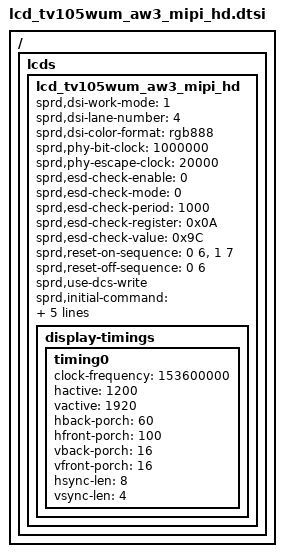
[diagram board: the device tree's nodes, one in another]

/*
 * tv105wum LCD config dtsi file for spreadtrum
 *
 * Copyright (C) 2018, Spreadtrum Communications Inc.
 * Copyright (C) 2023 Anhui Yunshu Zhihui Technology Co., Ltd.
 *
 * SPDX-License-Identifier: (GPL-2.0+ OR MIT)
 */

/ { lcds {
	lcd_tv105wum_aw3_mipi_hd: lcd_tv105wum_aw3_mipi_hd {

		sprd,dsi-work-mode = <1>; /* video burst mode*/
		sprd,dsi-lane-number = <4>;
		sprd,dsi-color-format = "rgb888";

		sprd,phy-bit-clock = <1000000>;	/* kbps */
		sprd,phy-escape-clock = <20000>;/* kHz */

		/*
		sprd,width-mm = <68>;
		sprd,height-mm = <121>;
		*/

		sprd,esd-check-enable = <0>;
		sprd,esd-check-mode = <0>;
		sprd,esd-check-period = <1000>;
		sprd,esd-check-register = <0x0A>;
		sprd,esd-check-value = <0x9C>;

		sprd,reset-on-sequence = <0 6>, <1 7>;
		sprd,reset-off-sequence = <0 6>;

		sprd,use-dcs-write;
		sprd,initial-command = [
		15 00 00 02 B0 05
		15 00 00 02 B1 E5
		15 00 00 02 B3 52
		15 00 00 02 B0 00
		//15 00 00 02 B3 88
		15 00 00 02 B0 04
		15 00 00 02 B8 00
		15 00 00 02 B0 00
		15 00 00 02 B6 03
		15 00 00 02 B2 50
		15 00 00 02 BA 87
		15 00 00 02 BF 1F
		15 00 00 02 C0 0F
		15 00 00 02 C2 0C
		15 00 00 02 C3 02
		15 00 00 02 C4 0C
		15 00 00 02 C5 02
		15 00 00 02 B0 01
		15 00 00 02 E0 26
		15 00 00 02 E1 26
		15 00 00 02 DC 00
		15 00 00 02 DD 00
		15 00 00 02 CC 26
		15 00 00 02 CD 26
		15 00 00 02 C8 00
		15 00 00 02 C9 00
		15 00 00 02 D2 04
		15 00 00 02 D3 04
		15 00 00 02 E6 03
		15 00 00 02 E7 03
		15 00 00 02 C4 08
		15 00 00 02 C5 08
		15 00 00 02 D8 07
		15 00 00 02 D9 07
		15 00 00 02 C2 06
		15 00 00 02 C3 06
		15 00 00 02 D6 05
		15 00 00 02 D7 05
		15 00 00 02 C0 0C
		15 00 00 02 C1 0C
		15 00 00 02 D4 0B
		15 00 00 02 D5 0B
		15 00 00 02 CA 0A
		15 00 00 02 CB 0A
		15 00 00 02 DE 09
		15 00 00 02 DF 09
		15 00 00 02 C6 26
		15 00 00 02 C7 26
		15 00 00 02 CE 00
		15 00 00 02 CF 00
		15 00 00 02 DA 26
		15 00 00 02 DB 26
		15 00 00 02 E2 00
		15 00 00 02 E3 00
		15 00 00 02 B0 02
		15 00 00 02 C0 00
		15 00 00 02 C1 0F
		15 00 00 02 C2 1A
		15 00 00 02 C3 2B
		15 00 00 02 C4 38
		15 00 00 02 C5 39
		15 00 00 02 C6 38
		15 00 00 02 C7 38
		15 00 00 02 C8 36
		15 00 00 02 C9 34
		15 00 00 02 CA 35
		15 00 00 02 CB 36
		15 00 00 02 CC 39
		15 00 00 02 CD 2D
		15 00 00 02 CE 2E
		15 00 00 02 CF 2F
		15 00 00 02 D0 07
		15 00 00 02 D2 00
		15 00 00 02 D3 0F
		15 00 00 02 D4 1A
		15 00 00 02 D5 2B
		15 00 00 02 D6 38
		15 00 00 02 D7 39
		15 00 00 02 D8 38
		15 00 00 02 D9 38
		15 00 00 02 DA 36
		15 00 00 02 DB 34
		15 00 00 02 DC 35
		15 00 00 02 DD 36
		15 00 00 02 DE 39
		15 00 00 02 DF 2D
		15 00 00 02 E0 2E
		15 00 00 02 E1 2F
		15 00 00 02 E2 07
		15 00 00 02 B0 03
		15 00 00 02 C8 0B
		15 00 00 02 C9 07
		15 00 00 02 C3 00
		15 00 00 02 E7 00
		15 00 00 02 C5 2A
		15 00 00 02 DE 2A
		15 00 00 02 CA 43
		15 00 00 02 C9 07
		15 00 00 02 E4 C0
		15 00 00 02 E5 0D
		15 00 00 02 CB 00
		15 00 00 02 B0 06
		15 00 00 02 B8 A5
		15 00 00 02 C0 A5
		15 00 00 02 C7 0F
		15 00 00 02 D5 32
		15 00 00 02 BC 33
		15 00 00 02 B0 07
		15 00 00 02 B1 00
		15 00 00 02 B2 04
		15 00 00 02 B3 0C
		15 00 00 02 B4 1B
		15 00 00 02 B5 2A
		15 00 00 02 B6 39
		15 00 00 02 B7 57
		15 00 00 02 B8 77
		15 00 00 02 B9 B9
		15 00 00 02 BA FE
		15 00 00 02 BB 7A
		15 00 00 02 BC F8
		15 00 00 02 BD FC
		15 00 00 02 BE 71
		15 00 00 02 BF DF
		15 00 00 02 C0 15
		15 00 00 02 C1 4C
		15 00 00 02 C2 64
		15 00 00 02 C3 7E
		15 00 00 02 C4 8A
		15 00 00 02 C5 95
		15 00 00 02 C6 A4
		15 00 00 02 C7 AA
		15 00 00 02 C8 B0
		15 00 00 02 C9 00
		15 00 00 02 CA 00
		15 00 00 02 CB 05
		15 00 00 02 CC 6B
		15 00 00 02 CD FF
		15 00 00 02 CE FF
		15 00 00 02 B0 08
		15 00 00 02 B1 00
		15 00 00 02 B2 04
		15 00 00 02 B3 0D
		15 00 00 02 B4 1F
		15 00 00 02 B5 31
		15 00 00 02 B6 43
		15 00 00 02 B7 66
		15 00 00 02 B8 8A
		15 00 00 02 B9 D5
		15 00 00 02 BA 1A
		15 00 00 02 BB A3
		15 00 00 02 BC 2F
		15 00 00 02 BD 33
		15 00 00 02 BE B2
		15 00 00 02 BF 2D
		15 00 00 02 C0 67
		15 00 00 02 C1 9F
		15 00 00 02 C2 BA
		15 00 00 02 C3 D3
		15 00 00 02 C4 DF
		15 00 00 02 C5 EB
		15 00 00 02 C6 F4
		15 00 00 02 C7 FA
		15 00 00 02 C8 FC
		15 00 00 02 C9 00
		15 00 00 02 CA 00
		15 00 00 02 CB 16
		15 00 00 02 CC AF
		15 00 00 02 CD FF
		15 00 00 02 CE FF
		15 00 00 02 B0 09
		15 00 00 02 B1 00
		15 00 00 02 B2 04
		15 00 00 02 B3 0C
		15 00 00 02 B4 1C
		15 00 00 02 B5 2C
		15 00 00 02 B6 3C
		15 00 00 02 B7 5C
		15 00 00 02 B8 81
		15 00 00 02 B9 CB
		15 00 00 02 BA 12
		15 00 00 02 BB 99
		15 00 00 02 BC 21
		15 00 00 02 BD 26
		15 00 00 02 BE A2
		15 00 00 02 BF 18
		15 00 00 02 C0 50
		15 00 00 02 C1 84
		15 00 00 02 C2 9F
		15 00 00 02 C3 B9
		15 00 00 02 C4 C3
		15 00 00 02 C5 CE
		15 00 00 02 C6 D9
		15 00 00 02 C7 DD
		15 00 00 02 C8 E1
		15 00 00 02 C9 00
		15 00 00 02 CA 00
		15 00 00 02 CB 16
		15 00 00 02 CC AF
		15 00 00 02 CD FF
		15 00 00 02 CE FF
		15 00 00 02 B0 0A
		15 00 00 02 B1 00
		15 00 00 02 B2 04
		15 00 00 02 B3 0C
		15 00 00 02 B4 1B
		15 00 00 02 B5 2A
		15 00 00 02 B6 39
		15 00 00 02 B7 57
		15 00 00 02 B8 77
		15 00 00 02 B9 B9
		15 00 00 02 BA FE
		15 00 00 02 BB 7A
		15 00 00 02 BC F8
		15 00 00 02 BD FC
		15 00 00 02 BE 71
		15 00 00 02 BF DF
		15 00 00 02 C0 15
		15 00 00 02 C1 4C
		15 00 00 02 C2 64
		15 00 00 02 C3 7E
		15 00 00 02 C4 8A
		15 00 00 02 C5 95
		15 00 00 02 C6 A4
		15 00 00 02 C7 AA
		15 00 00 02 C8 B0
		15 00 00 02 C9 00
		15 00 00 02 CA 00
		15 00 00 02 CB 05
		15 00 00 02 CC 6B
		15 00 00 02 CD FF
		15 00 00 02 CE FF
		15 00 00 02 B0 0B
		15 00 00 02 B1 00
		15 00 00 02 B2 04
		15 00 00 02 B3 0D
		15 00 00 02 B4 1F
		15 00 00 02 B5 31
		15 00 00 02 B6 43
		15 00 00 02 B7 66
		15 00 00 02 B8 8A
		15 00 00 02 B9 D5
		15 00 00 02 BA 1A
		15 00 00 02 BB A3
		15 00 00 02 BC 2F
		15 00 00 02 BD 33
		15 00 00 02 BE B2
		15 00 00 02 BF 2D
		15 00 00 02 C0 67
		15 00 00 02 C1 9F
		15 00 00 02 C2 BA
		15 00 00 02 C3 D3
		15 00 00 02 C4 DF
		15 00 00 02 C5 EB
		15 00 00 02 C6 F4
		15 00 00 02 C7 FA
		15 00 00 02 C8 FC
		15 00 00 02 C9 00
		15 00 00 02 CA 00
		15 00 00 02 CB 16
		15 00 00 02 CC AF
		15 00 00 02 CD FF
		15 00 00 02 CE FF
		15 00 00 02 B0 0C
		15 00 00 02 B1 00
		15 00 00 02 B2 04
		15 00 00 02 B3 0C
		15 00 00 02 B4 1C
		15 00 00 02 B5 2C
		15 00 00 02 B6 3C
		15 00 00 02 B7 5C
		15 00 00 02 B8 81
		15 00 00 02 B9 CB
		15 00 00 02 BA 12
		15 00 00 02 BB 99
		15 00 00 02 BC 21
		15 00 00 02 BD 26
		15 00 00 02 BE A2
		15 00 00 02 BF 18
		15 00 00 02 C0 50
		15 00 00 02 C1 84
		15 00 00 02 C2 9F
		15 00 00 02 C3 B9
		15 00 00 02 C4 C3
		15 00 00 02 C5 CE
		15 00 00 02 C6 D9
		15 00 00 02 C7 DD
		15 00 00 02 C8 E1
		15 00 00 02 C9 00
		15 00 00 02 CA 00
		15 00 00 02 CB 16
		15 00 00 02 CC AF
		15 00 00 02 CD FF
		15 00 00 02 CE FF
		15 00 00 02 B0 00
		15 00 00 02 B3 08
		15 00 00 02 B0 04
		15 00 00 02 B8 68
		15 00 00 02 B0 00
		05 64 00 01 11
		05 32 00 01 29
			];

		sprd,sleep-in-command = [
            13 0A 00 01 28
            13 65 00 01 10
			];

		sprd,sleep-out-command = [
            13 64 00 01 11
            13 32 00 01 29
			];

		display-timings {
			timing0 {
				clock-frequency = <153600000>;
				hactive = <1200>;
				vactive = <1920>;
				hback-porch = <60>;
				hfront-porch = <100>;
				vback-porch = <16>;
				vfront-porch = <16>;
				hsync-len = <8>;
				vsync-len = <4>;
			};
		};
	};
};};
